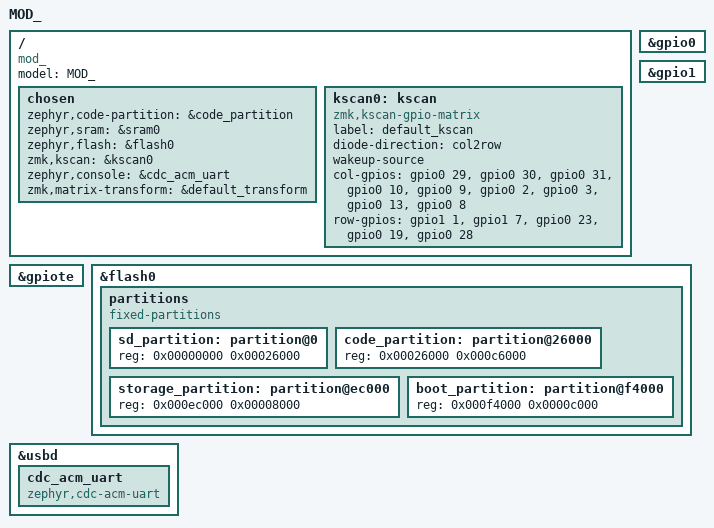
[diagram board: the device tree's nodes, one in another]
/*
 * copyright (c) 2025 ZMK project contributors
 *
 * SPDX-license-identifier: MIT
 */

/dts-v1/;

#include <nordic/nrf52833_qiaa.dtsi>

#include <dt-bindings/zmk/matrix_transform.h>

/ {
    model = "MOD_";
    compatible = "mod_";

    chosen {
        zephyr,code-partition = &code_partition;
        zephyr,sram = &sram0;
        zephyr,flash = &flash0;
        zmk,kscan = &kscan0;
        zephyr,console = &cdc_acm_uart;
        zmk,matrix-transform = &default_transform;
    };

    kscan0: kscan {
        compatible = "zmk,kscan-gpio-matrix";
        label = "default_kscan";
        diode-direction = "col2row";
        wakeup-source;

        col-gpios = <&gpio0 29 GPIO_ACTIVE_HIGH>,
                    <&gpio0 30 GPIO_ACTIVE_HIGH>,
                    <&gpio0 31 GPIO_ACTIVE_HIGH>,
                    <&gpio0 10 GPIO_ACTIVE_HIGH>,
                    <&gpio0 9  GPIO_ACTIVE_HIGH>,
                    <&gpio0 2  GPIO_ACTIVE_HIGH>,
                    <&gpio0 3  GPIO_ACTIVE_HIGH>,
                    <&gpio0 13 GPIO_ACTIVE_HIGH>,
                    <&gpio0 8  GPIO_ACTIVE_HIGH>;

        row-gpios = <&gpio1 1  (GPIO_ACTIVE_HIGH | GPIO_PULL_DOWN)>,
                    <&gpio1 7  (GPIO_ACTIVE_HIGH | GPIO_PULL_DOWN)>,
                    <&gpio0 23 (GPIO_ACTIVE_HIGH | GPIO_PULL_DOWN)>,
                    <&gpio0 19 (GPIO_ACTIVE_HIGH | GPIO_PULL_DOWN)>,
                    <&gpio0 28 (GPIO_ACTIVE_HIGH | GPIO_PULL_DOWN)>;
    };
};

&gpiote {
    status = "okay";
};

&gpio0 {
    status = "okay";
};

&gpio1 {
    status = "okay";
};

&flash0 {
    /*
     * For more information, see:
     * http://docs.zephyrproject.org/latest/devices/dts/flash_partitions.html
     */
    partitions {
        compatible = "fixed-partitions";
        #address-cells = <1>;
        #size-cells = <1>;

        sd_partition: partition@0 {
            reg = <0x00000000 0x00026000>;
        };
        code_partition: partition@26000 {
            reg = <0x00026000 0x000c6000>;
        };

        /*
         * The flash starting at 0x000ec000 and ending at
         * 0x000f3fff is reserved for use by the application.
         */

        /*
         * Storage partition will be used by FCB/LittleFS/NVS
         * if enabled.
         */
        storage_partition: partition@ec000 {
            reg = <0x000ec000 0x00008000>;
        };

        boot_partition: partition@f4000 {
            reg = <0x000f4000 0x0000c000>;
        };
    };
};

&usbd {
    status = "okay";
    cdc_acm_uart: cdc_acm_uart {
        compatible = "zephyr,cdc-acm-uart";
    };
};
